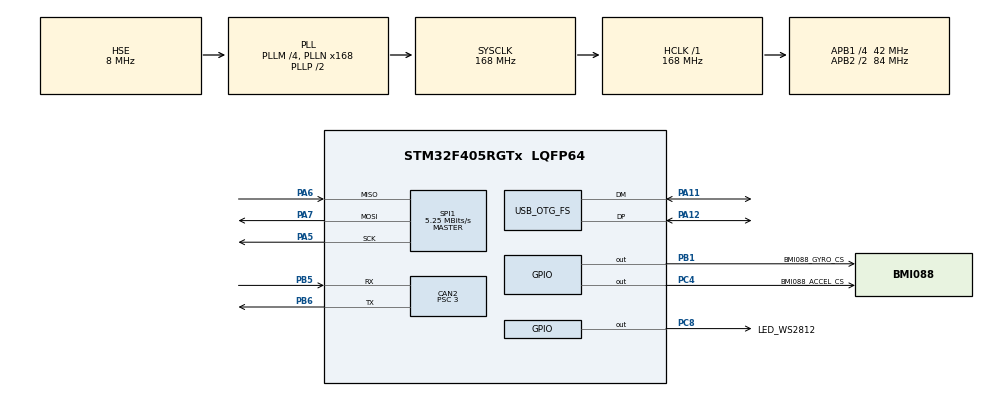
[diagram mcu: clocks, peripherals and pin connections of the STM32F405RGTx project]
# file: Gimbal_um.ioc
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CAN2.BS1=CAN_BS1_11TQ
CAN2.BS2=CAN_BS2_2TQ
CAN2.CalculateBaudRate=1000000
CAN2.CalculateTimeBit=1000
CAN2.CalculateTimeQuantum=71.42857142857143
CAN2.Prescaler=3
Dma.Request0=SPI1_RX
Dma.Request1=SPI1_TX
Dma.SPI1_RX.0.Direction=DMA_PERIPH_TO_MEMORY
Dma.SPI1_RX.0.FIFOMode=DMA_FIFOMODE_DISABLE
Dma.SPI1_RX.0.Instance=DMA2_Stream0
Dma.SPI1_RX.0.MemDataAlignment=DMA_MDATAALIGN_BYTE
Dma.SPI1_RX.0.MemInc=DMA_MINC_ENABLE
Dma.SPI1_RX.0.Mode=DMA_NORMAL
Dma.SPI1_RX.0.PeriphDataAlignment=DMA_PDATAALIGN_BYTE
Dma.SPI1_RX.0.PeriphInc=DMA_PINC_DISABLE
Dma.SPI1_RX.0.Priority=DMA_PRIORITY_LOW
Dma.SPI1_TX.1.Direction=DMA_MEMORY_TO_PERIPH
Dma.SPI1_TX.1.FIFOMode=DMA_FIFOMODE_DISABLE
Dma.SPI1_TX.1.Instance=DMA2_Stream3
Dma.SPI1_TX.1.MemDataAlignment=DMA_MDATAALIGN_BYTE
Dma.SPI1_TX.1.MemInc=DMA_MINC_ENABLE
Dma.SPI1_TX.1.Mode=DMA_NORMAL
Dma.SPI1_TX.1.PeriphDataAlignment=DMA_PDATAALIGN_BYTE
Dma.SPI1_TX.1.PeriphInc=DMA_PINC_DISABLE
Dma.SPI1_TX.1.Priority=DMA_PRIORITY_LOW
FREERTOS.BinarySemaphores01=comm_sem,Dynamic,NULL,Available
FREERTOS.Tasks01=defaultTask,24,128,StartDefaultTask,Default,NULL,Dynamic,NULL,NULL;CtrlTask,48,1024,StartCtrlTask,As weak,NULL,Dynamic,NULL,NULL;CommunicateTask,40,1024,StartCommunicateTask,As weak,NULL,Dynamic,NULL,NULL;dddebugTask,48,512,StartdddebugTask,As weak,NULL,Dynamic,NULL,NULL;RTTTask,41,128,StartRTTTask,As weak,NULL,Dynamic,NULL,NULL
Mcu.Family=STM32F4
Mcu.Name=STM32F405RGTx
Mcu.Package=LQFP64
NVIC.CAN2_RX0_IRQn=true\:5\:0\:false\:false\:true\:true\:true\:true\:true
NVIC.CAN2_TX_IRQn=true\:5\:0\:false\:false\:true\:true\:true\:true\:true
NVIC.DMA2_Stream0_IRQn=true\:5\:0\:false\:false\:true\:true\:false\:true\:true
NVIC.DMA2_Stream3_IRQn=true\:5\:0\:false\:false\:true\:true\:false\:true\:true
NVIC.OTG_FS_IRQn=true\:5\:0\:false\:false\:true\:true\:false\:true\:true
NVIC.PriorityGroup=NVIC_PRIORITYGROUP_4
NVIC.TIM6_DAC_IRQn=true\:15\:0\:false\:false\:true\:false\:false\:true\:true
NVIC.TimeBase=TIM6_DAC_IRQn
NVIC.TimeBaseIP=TIM6
PA11.Mode=Device_Only
PA11.Signal=USB_OTG_FS_DM
PA12.Mode=Device_Only
PA12.Signal=USB_OTG_FS_DP
PA13.Mode=Serial_Wire
PA13.Signal=SYS_JTMS-SWDIO
PA14.Mode=Serial_Wire
PA14.Signal=SYS_JTCK-SWCLK
PA5.Mode=Full_Duplex_Master
PA5.Signal=SPI1_SCK
PA6.Mode=Full_Duplex_Master
PA6.Signal=SPI1_MISO
PA7.Mode=Full_Duplex_Master
PA7.Signal=SPI1_MOSI
PB1.GPIO_Label=BMI088_GYRO_CS
PB1.PinState=GPIO_PIN_SET
PB1.Signal=GPIO_Output
PB5.Mode=CAN_Activate
PB5.Signal=CAN2_RX
PB6.Mode=CAN_Activate
PB6.Signal=CAN2_TX
PC4.GPIO_Label=BMI088_ACCEL_CS
PC4.PinState=GPIO_PIN_SET
PC4.Signal=GPIO_Output
PC8.GPIO_Label=LED_WS2812
PC8.Signal=GPIO_Output
PH0-OSC_IN.Mode=HSE-External-Oscillator
PH0-OSC_IN.Signal=RCC_OSC_IN
PH1-OSC_OUT.Mode=HSE-External-Oscillator
PH1-OSC_OUT.Signal=RCC_OSC_OUT
ProjectManager.HeapSize=0x200
ProjectManager.StackSize=0x400
ProjectManager.TargetToolchain=CMake
RCC.48MHZClocksFreq_Value=48000000
RCC.AHBFreq_Value=168000000
RCC.APB1CLKDivider=RCC_HCLK_DIV4
RCC.APB1Freq_Value=42000000
RCC.APB1TimFreq_Value=84000000
RCC.APB2CLKDivider=RCC_HCLK_DIV2
RCC.APB2Freq_Value=84000000
RCC.APB2TimFreq_Value=168000000
RCC.CortexFreq_Value=168000000
RCC.HCLKFreq_Value=168000000
RCC.HSE_VALUE=8000000
RCC.HSI_VALUE=16000000
RCC.LSE_VALUE=32768
RCC.PLLM=4
RCC.PLLN=168
RCC.PLLQ=7
RCC.SYSCLKFreq_VALUE=168000000
RCC.SYSCLKSource=RCC_SYSCLKSOURCE_PLLCLK
RCC.VCOOutputFreq_Value=336000000
SPI1.BaudRatePrescaler=SPI_BAUDRATEPRESCALER_16
SPI1.CalculateBaudRate=5.25 MBits/s
SPI1.Direction=SPI_DIRECTION_2LINES
SPI1.Mode=SPI_MODE_MASTER
SPI1.VirtualType=VM_MASTER
USB_DEVICE.CLASS_NAME_FS=CDC
USB_DEVICE.VirtualMode-CDC_FS=Cdc
USB_DEVICE.VirtualModeFS=Cdc_FS
USB_OTG_FS.VirtualMode=Device_Only
VP_FREERTOS_VS_CMSIS_V2.Mode=CMSIS_V2
VP_SYS_VS_tim6.Mode=TIM6
VP_USB_DEVICE_VS_USB_DEVICE_CDC_FS.Mode=CDC_FS
board=custom

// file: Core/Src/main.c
/* USER CODE BEGIN Header */
/**
  ******************************************************************************
  * @file           : main.c
  * @brief          : Main program body
  ******************************************************************************
  * @attention
  *
  * Copyright (c) 2026 STMicroelectronics.
  * All rights reserved.
  *
  * This software is licensed under terms that can be found in the LICENSE file
  * in the root directory of this software component.
  * If no LICENSE file comes with this software, it is provided AS-IS.
  *
  ******************************************************************************
  */
/* USER CODE END Header */
#include "main.h"
#include "cmsis_os.h"
#include "usb_device.h"

/* USER CODE BEGIN Includes */
#include "bsp_can.h"
/* USER CODE END Includes */

CAN_HandleTypeDef hcan2;

SPI_HandleTypeDef hspi1;
DMA_HandleTypeDef hdma_spi1_rx;
DMA_HandleTypeDef hdma_spi1_tx;

/* Definitions for defaultTask */
osThreadId_t defaultTaskHandle;
const osThreadAttr_t defaultTask_attributes = {
  .name = "defaultTask",
  .stack_size = 128 * 4,
  .priority = (osPriority_t) osPriorityNormal,
};
/* Definitions for CtrlTask */
osThreadId_t CtrlTaskHandle;
const osThreadAttr_t CtrlTask_attributes = {
  .name = "CtrlTask",
  .stack_size = 1024 * 4,
  .priority = (osPriority_t) osPriorityRealtime,
};
/* Definitions for CommunicateTask */
osThreadId_t CommunicateTaskHandle;
const osThreadAttr_t CommunicateTask_attributes = {
  .name = "CommunicateTask",
  .stack_size = 1024 * 4,
  .priority = (osPriority_t) osPriorityHigh,
};
/* Definitions for dddebugTask */
osThreadId_t dddebugTaskHandle;
const osThreadAttr_t dddebugTask_attributes = {
  .name = "dddebugTask",
  .stack_size = 512 * 4,
  .priority = (osPriority_t) osPriorityRealtime,
};
/* Definitions for RTTTask */
osThreadId_t RTTTaskHandle;
const osThreadAttr_t RTTTask_attributes = {
  .name = "RTTTask",
  .stack_size = 512 * 4,
  .priority = (osPriority_t) osPriorityHigh1,
};
/* Definitions for comm_sem */
osSemaphoreId_t comm_semHandle;
const osSemaphoreAttr_t comm_sem_attributes = {
  .name = "comm_sem"
};

void SystemClock_Config(void);
static void MX_GPIO_Init(void);
static void MX_DMA_Init(void);
static void MX_SPI1_Init(void);
static void MX_CAN2_Init(void);
void StartDefaultTask(void *argument);
void StartCtrlTask(void *argument);
void StartCommunicateTask(void *argument);
void StartdddebugTask(void *argument);
void StartRTTTask(void *argument);

int main(void)
{

  /* MCU Configuration--------------------------------------------------------*/

  /* Reset of all peripherals, Initializes the Flash interface and the Systick. */
  HAL_Init();

  /* Configure the system clock */
  SystemClock_Config();

  /* Initialize all configured peripherals */
  MX_GPIO_Init();
  MX_DMA_Init();
  MX_SPI1_Init();
  MX_CAN2_Init();
  /* USER CODE BEGIN 2 */

  // bsp_can_init();

  /* USER CODE END 2 */

  /* Init scheduler */
  osKernelInitialize();

  /* Create the semaphores(s) */
  /* creation of comm_sem */
  comm_semHandle = osSemaphoreNew(1, 1, &comm_sem_attributes);

  /* Create the thread(s) */
  /* creation of defaultTask */
  defaultTaskHandle = osThreadNew(StartDefaultTask, NULL, &defaultTask_attributes);

  /* creation of CtrlTask */
  CtrlTaskHandle = osThreadNew(StartCtrlTask, NULL, &CtrlTask_attributes);

  /* creation of CommunicateTask */
  CommunicateTaskHandle = osThreadNew(StartCommunicateTask, NULL, &CommunicateTask_attributes);

  /* creation of dddebugTask */
  dddebugTaskHandle = osThreadNew(StartdddebugTask, NULL, &dddebugTask_attributes);

  /* creation of RTTTask */
  RTTTaskHandle = osThreadNew(StartRTTTask, NULL, &RTTTask_attributes);

  /* Start scheduler */
  osKernelStart();

  /* We should never get here as control is now taken by the scheduler */

  /* Infinite loop */
  while (1)
  {

  }
}

void SystemClock_Config(void)
{
  RCC_OscInitTypeDef RCC_OscInitStruct = {0};
  RCC_ClkInitTypeDef RCC_ClkInitStruct = {0};

  /** Configure the main internal regulator output voltage
  */
  __HAL_RCC_PWR_CLK_ENABLE();
  __HAL_PWR_VOLTAGESCALING_CONFIG(PWR_REGULATOR_VOLTAGE_SCALE1);

  /** Initializes the RCC Oscillators according to the specified parameters
  * in the RCC_OscInitTypeDef structure.
  */
  RCC_OscInitStruct.OscillatorType = RCC_OSCILLATORTYPE_HSE;
  RCC_OscInitStruct.HSEState = RCC_HSE_ON;
  RCC_OscInitStruct.PLL.PLLState = RCC_PLL_ON;
  RCC_OscInitStruct.PLL.PLLSource = RCC_PLLSOURCE_HSE;
  RCC_OscInitStruct.PLL.PLLM = 4;
  RCC_OscInitStruct.PLL.PLLN = 168;
  RCC_OscInitStruct.PLL.PLLP = RCC_PLLP_DIV2;
  RCC_OscInitStruct.PLL.PLLQ = 7;
  if (HAL_RCC_OscConfig(&RCC_OscInitStruct) != HAL_OK)
  {
    Error_Handler();
  }

  /** Initializes the CPU, AHB and APB buses clocks
  */
  RCC_ClkInitStruct.ClockType = RCC_CLOCKTYPE_HCLK|RCC_CLOCKTYPE_SYSCLK
                              |RCC_CLOCKTYPE_PCLK1|RCC_CLOCKTYPE_PCLK2;
  RCC_ClkInitStruct.SYSCLKSource = RCC_SYSCLKSOURCE_PLLCLK;
  RCC_ClkInitStruct.AHBCLKDivider = RCC_SYSCLK_DIV1;
  RCC_ClkInitStruct.APB1CLKDivider = RCC_HCLK_DIV4;
  RCC_ClkInitStruct.APB2CLKDivider = RCC_HCLK_DIV2;

  if (HAL_RCC_ClockConfig(&RCC_ClkInitStruct, FLASH_LATENCY_5) != HAL_OK)
  {
    Error_Handler();
  }
}

static void MX_CAN2_Init(void)
{

  hcan2.Instance = CAN2;
  hcan2.Init.Prescaler = 3;
  hcan2.Init.Mode = CAN_MODE_NORMAL;
  hcan2.Init.SyncJumpWidth = CAN_SJW_1TQ;
  hcan2.Init.TimeSeg1 = CAN_BS1_11TQ;
  hcan2.Init.TimeSeg2 = CAN_BS2_2TQ;
  hcan2.Init.TimeTriggeredMode = DISABLE;
  hcan2.Init.AutoBusOff = DISABLE;
  hcan2.Init.AutoWakeUp = DISABLE;
  hcan2.Init.AutoRetransmission = DISABLE;
  hcan2.Init.ReceiveFifoLocked = DISABLE;
  hcan2.Init.TransmitFifoPriority = DISABLE;
  if (HAL_CAN_Init(&hcan2) != HAL_OK)
  {
    Error_Handler();
  }

}

static void MX_SPI1_Init(void)
{

  /* SPI1 parameter configuration*/
  hspi1.Instance = SPI1;
  hspi1.Init.Mode = SPI_MODE_MASTER;
  hspi1.Init.Direction = SPI_DIRECTION_2LINES;
  hspi1.Init.DataSize = SPI_DATASIZE_8BIT;
  hspi1.Init.CLKPolarity = SPI_POLARITY_LOW;
  hspi1.Init.CLKPhase = SPI_PHASE_1EDGE;
  hspi1.Init.NSS = SPI_NSS_SOFT;
  hspi1.Init.BaudRatePrescaler = SPI_BAUDRATEPRESCALER_16;
  hspi1.Init.FirstBit = SPI_FIRSTBIT_MSB;
  hspi1.Init.TIMode = SPI_TIMODE_DISABLE;
  hspi1.Init.CRCCalculation = SPI_CRCCALCULATION_DISABLE;
  hspi1.Init.CRCPolynomial = 10;
  if (HAL_SPI_Init(&hspi1) != HAL_OK)
  {
    Error_Handler();
  }

}

static void MX_DMA_Init(void)
{

  /* DMA controller clock enable */
  __HAL_RCC_DMA2_CLK_ENABLE();

  /* DMA interrupt init */
  /* DMA2_Stream0_IRQn interrupt configuration */
  HAL_NVIC_SetPriority(DMA2_Stream0_IRQn, 5, 0);
  HAL_NVIC_EnableIRQ(DMA2_Stream0_IRQn);
  /* DMA2_Stream3_IRQn interrupt configuration */
  HAL_NVIC_SetPriority(DMA2_Stream3_IRQn, 5, 0);
  HAL_NVIC_EnableIRQ(DMA2_Stream3_IRQn);

}

static void MX_GPIO_Init(void)
{
  GPIO_InitTypeDef GPIO_InitStruct = {0};

  /* GPIO Ports Clock Enable */
  __HAL_RCC_GPIOH_CLK_ENABLE();
  __HAL_RCC_GPIOA_CLK_ENABLE();
  __HAL_RCC_GPIOC_CLK_ENABLE();
  __HAL_RCC_GPIOB_CLK_ENABLE();

  /*Configure GPIO pin Output Level */
  HAL_GPIO_WritePin(BMI088_ACCEL_CS_GPIO_Port, BMI088_ACCEL_CS_Pin, GPIO_PIN_SET);

  /*Configure GPIO pin Output Level */
  HAL_GPIO_WritePin(BMI088_GYRO_CS_GPIO_Port, BMI088_GYRO_CS_Pin, GPIO_PIN_SET);

  /*Configure GPIO pin Output Level */
  HAL_GPIO_WritePin(LED_WS2812_GPIO_Port, LED_WS2812_Pin, GPIO_PIN_RESET);

  /*Configure GPIO pins : BMI088_ACCEL_CS_Pin LED_WS2812_Pin */
  GPIO_InitStruct.Pin = BMI088_ACCEL_CS_Pin|LED_WS2812_Pin;
  GPIO_InitStruct.Mode = GPIO_MODE_OUTPUT_PP;
  GPIO_InitStruct.Pull = GPIO_NOPULL;
  GPIO_InitStruct.Speed = GPIO_SPEED_FREQ_LOW;
  HAL_GPIO_Init(GPIOC, &GPIO_InitStruct);

  /*Configure GPIO pin : BMI088_GYRO_CS_Pin */
  GPIO_InitStruct.Pin = BMI088_GYRO_CS_Pin;
  GPIO_InitStruct.Mode = GPIO_MODE_OUTPUT_PP;
  GPIO_InitStruct.Pull = GPIO_NOPULL;
  GPIO_InitStruct.Speed = GPIO_SPEED_FREQ_LOW;
  HAL_GPIO_Init(BMI088_GYRO_CS_GPIO_Port, &GPIO_InitStruct);

}

void StartDefaultTask(void *argument)
{
  /* init code for USB_DEVICE */
  MX_USB_DEVICE_Init();
  for(;;)
  {
    osDelay(1);
  }
}

__weak void StartCtrlTask(void *argument)
{
  for(;;)
  {
    osDelay(1);
  }
}

__weak void StartCommunicateTask(void *argument)
{
  for(;;)
  {
    osDelay(1);
  }
}

__weak void StartdddebugTask(void *argument)
{
  for(;;)
  {
    osDelay(1);
  }
}

__weak void StartRTTTask(void *argument)
{
  for(;;)
  {
    osDelay(1);
  }
}

void HAL_TIM_PeriodElapsedCallback(TIM_HandleTypeDef *htim)
{
  if (htim->Instance == TIM6)
  {
    HAL_IncTick();
  }
}

void Error_Handler(void)
{
  __disable_irq();
  while (1)
  {
  }
}
